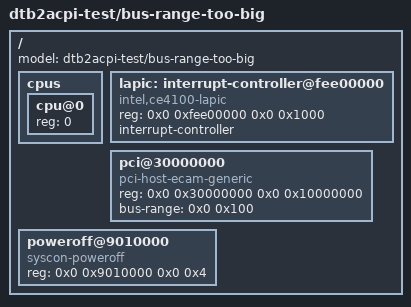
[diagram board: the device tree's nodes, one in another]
/dts-v1/;

/ {
	#address-cells = <2>;
	#size-cells = <2>;
	model = "dtb2acpi-test/bus-range-too-big";

	cpus {
		#address-cells = <1>;
		#size-cells = <0>;
		cpu@0 {
			device_type = "cpu";
			reg = <0>;
		};
	};

		lapic: interrupt-controller@fee00000 {
		compatible = "intel,ce4100-lapic";
		reg = <0x0 0xfee00000 0x0 0x1000>;
		interrupt-controller;
		#interrupt-cells = <2>;
	};

	pci@30000000 {
		compatible = "pci-host-ecam-generic";
		#address-cells = <3>;
		#size-cells = <2>;
		reg = <0x0 0x30000000 0x0 0x10000000>;
		/* End bus > 0xFF — PCI buses are u8. */
		bus-range = <0x0 0x100>;
	};
		poweroff@9010000 {
		compatible = "syscon-poweroff";
		reg = <0x0 0x9010000 0x0 0x4>;
	};
};
